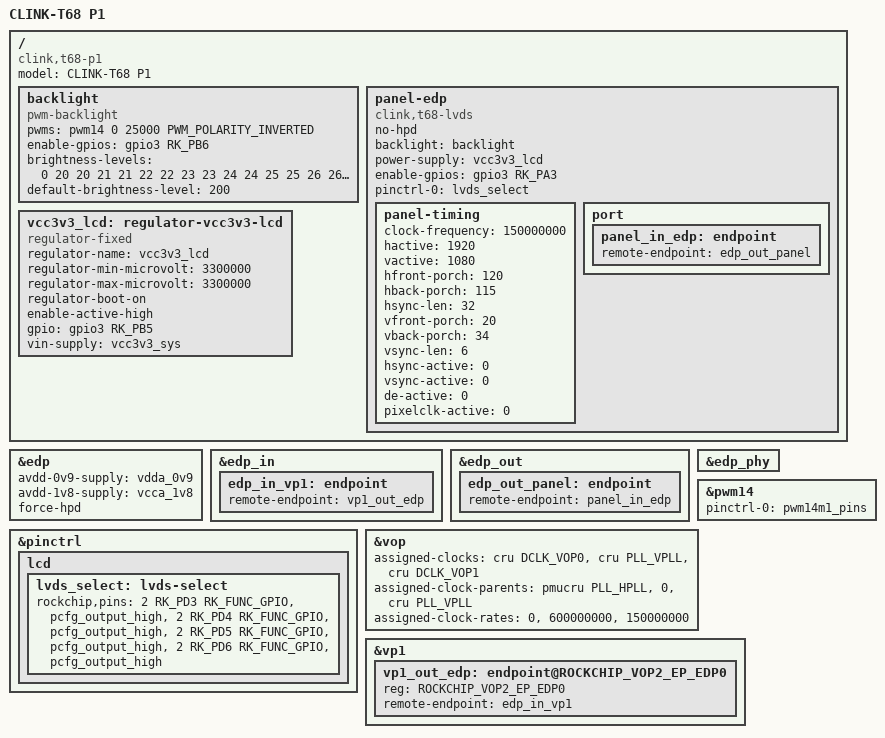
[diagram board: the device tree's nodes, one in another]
// SPDX-License-Identifier: (GPL-2.0+ OR MIT)
/*
 * Copyright (c) 2022 Fuzhou Rockchip Electronics Co., Ltd.
 * Copyright (c) 2026 retro98boy <retro98boy@qq.com>
 */

/* Add the CS5211 eDP-to-LVDS display to the base board. */
#include "rk3568-clink-t68.dts"
#include <dt-bindings/pwm/pwm.h>

/ {
	model = "CLINK-T68 P1";
	compatible = "clink,t68-p1", "clink,t68", "rockchip,rk3568";

	backlight: backlight {
		compatible = "pwm-backlight";
		pwms = <&pwm14 0 25000 PWM_POLARITY_INVERTED>;
		enable-gpios = <&gpio3 RK_PB6 GPIO_ACTIVE_HIGH>;
		brightness-levels = <
			0 20 20 21 21 22 22 23 23 24 24 25 25 26 26 27
			27 28 28 29 29 30 30 31 31 32 32 33 33 34 34 35
			35 36 36 37 37 38 38 39 40 41 42 43 44 45 46 47
			48 49 50 51 52 53 54 55 56 57 58 59 60 61 62 63
			64 65 66 67 68 69 70 71 72 73 74 75 76 77 78 79
			80 81 82 83 84 85 86 87 88 89 90 91 92 93 94 95
			96 97 98 99 100 101 102 103 104 105 106 107 108 109 110 111
			112 113 114 115 116 117 118 119 120 121 122 123 124 125 126 127
			128 129 130 131 132 133 134 135 136 137 138 139 140 141 142 143
			144 145 146 147 148 149 150 151 152 153 154 155 156 157 158 159
			160 161 162 163 164 165 166 167 168 169 170 171 172 173 174 175
			176 177 178 179 180 181 182 183 184 185 186 187 188 189 190 191
			192 193 194 195 196 197 198 199 200 201 202 203 204 205 206 207
			208 209 210 211 212 213 214 215 216 217 218 219 220 221 222 223
			224 225 226 227 228 229 230 231 232 233 234 235 236 237 238 239
			240 241 242 243 244 245 246 247 248 249 250 251 252 253 254 255
		>;
		default-brightness-level = <200>;
	};

	/* CS5211 uses GPIO straps. No I2C control interface is connected. */
	panel-edp {
		compatible = "clink,t68-lvds";
		no-hpd;
		backlight = <&backlight>;
		power-supply = <&vcc3v3_lcd>;
		enable-gpios = <&gpio3 RK_PA3 GPIO_ACTIVE_HIGH>;
		pinctrl-names = "default";
		pinctrl-0 = <&lvds_select>;

		panel-timing {
			clock-frequency = <150000000>;
			hactive = <1920>;
			vactive = <1080>;
			hfront-porch = <120>;
			hback-porch = <115>;
			hsync-len = <32>;
			vfront-porch = <20>;
			vback-porch = <34>;
			vsync-len = <6>;
			hsync-active = <0>;
			vsync-active = <0>;
			de-active = <0>;
			pixelclk-active = <0>;
		};

		port {
			panel_in_edp: endpoint {
				remote-endpoint = <&edp_out_panel>;
			};
		};
	};

	vcc3v3_lcd: regulator-vcc3v3-lcd {
		compatible = "regulator-fixed";
		regulator-name = "vcc3v3_lcd";
		regulator-min-microvolt = <3300000>;
		regulator-max-microvolt = <3300000>;
		regulator-boot-on;
		enable-active-high;
		gpio = <&gpio3 RK_PB5 GPIO_ACTIVE_HIGH>;
		vin-supply = <&vcc3v3_sys>;
	};
};

&edp {
	avdd-0v9-supply = <&vdda_0v9>;
	avdd-1v8-supply = <&vcca_1v8>;
	force-hpd;
	status = "okay";
};

&edp_in {
	edp_in_vp1: endpoint {
		remote-endpoint = <&vp1_out_edp>;
	};
};

&edp_out {
	edp_out_panel: endpoint {
		remote-endpoint = <&panel_in_edp>;
	};
};

&edp_phy {
	status = "okay";
};

&pinctrl {
	lcd {
		/* Preserve all four stock bridge selection levels. */
		lvds_select: lvds-select {
			rockchip,pins = <2 RK_PD3 RK_FUNC_GPIO &pcfg_output_high>,
					<2 RK_PD4 RK_FUNC_GPIO &pcfg_output_high>,
					<2 RK_PD5 RK_FUNC_GPIO &pcfg_output_high>,
					<2 RK_PD6 RK_FUNC_GPIO &pcfg_output_high>;
		};
	};
};

&pwm14 {
	pinctrl-0 = <&pwm14m1_pins>;
	status = "okay";
};

/* VPLL / 4 supplies the 150 MHz pixel clock for the CS5211 timing. */
&vop {
	assigned-clocks = <&cru DCLK_VOP0>, <&cru PLL_VPLL>, <&cru DCLK_VOP1>;
	assigned-clock-parents = <&pmucru PLL_HPLL>, <0>, <&cru PLL_VPLL>;
	assigned-clock-rates = <0>, <600000000>, <150000000>;
};

&vp1 {
	vp1_out_edp: endpoint@ROCKCHIP_VOP2_EP_EDP0 {
		reg = <ROCKCHIP_VOP2_EP_EDP0>;
		remote-endpoint = <&edp_in_vp1>;
	};
};
